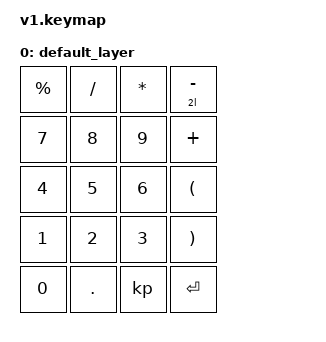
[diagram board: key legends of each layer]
// This file was generated from a template. Edit it to match your keyboard.
// See https://zmk.dev/docs/development/hardware-integration/new-shield for more instructions.

#include <behaviors.dtsi>
#include <dt-bindings/zmk/keys.h>

/ {
    // Define a default keymap here.
    // See https://zmk.dev/docs/development/hardware-integration/new-shield#default-keymap.
    keymap {
        compatible = "zmk,keymap";

        default_layer {
            bindings = <
                &kp % &kp / &kp * &lt 2l -
                &kp 7 &kp 8 &kp 9 &kp +
                &kp 4 &kp 5 &kp 6 &kp (
                &kp 1 &kp 2 &kp 3 &kp )
                &kp 0 &kp . &kp , &kp ENTER
            >;
        };
    };
};
